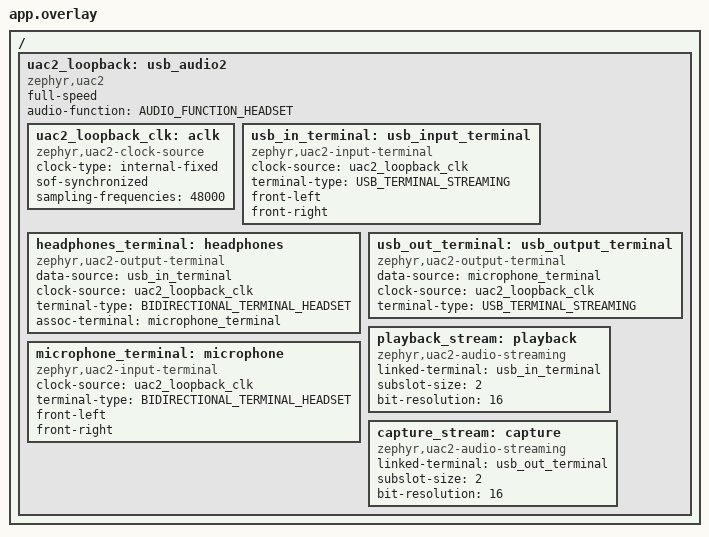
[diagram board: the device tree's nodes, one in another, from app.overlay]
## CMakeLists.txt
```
# SPDX-FileCopyrightText: Copyright The Zephyr Project Contributors
# SPDX-License-Identifier: Apache-2.0

cmake_minimum_required(VERSION 3.28.0)
find_package(Zephyr REQUIRED HINTS $ENV{ZEPHYR_BASE})
project(uac2_loopback)

include(${ZEPHYR_BASE}/samples/subsys/usb/common/common.cmake)
target_sources(app PRIVATE src/main.c)
```

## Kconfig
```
# SPDX-FileCopyrightText: Copyright The Zephyr Project Contributors
# SPDX-License-Identifier: Apache-2.0

source "samples/subsys/usb/common/Kconfig.sample_usbd"

source "Kconfig.zephyr"
```

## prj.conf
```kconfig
CONFIG_USB_DEVICE_STACK_NEXT=y
CONFIG_CDC_ACM_SERIAL_INITIALIZE_AT_BOOT=n
CONFIG_USBD_AUDIO2_CLASS=y
CONFIG_SAMPLE_USBD_PID=0x0014
CONFIG_SAMPLE_USBD_PRODUCT="UAC2 loopback sample"

CONFIG_LOG=y
CONFIG_USBD_LOG_LEVEL_WRN=y
CONFIG_UDC_DRIVER_LOG_LEVEL_WRN=y
```

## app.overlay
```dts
/*
 * SPDX-FileCopyrightText: Copyright The Zephyr Project Contributors
 * SPDX-License-Identifier: Apache-2.0
 */

#include <zephyr/dt-bindings/usb/audio.h>

/ {
	uac2_loopback: usb_audio2 {
		compatible = "zephyr,uac2";
		status = "okay";
		full-speed;
		audio-function = <AUDIO_FUNCTION_HEADSET>;

		uac2_loopback_clk: aclk {
			compatible = "zephyr,uac2-clock-source";
			clock-type = "internal-fixed";
			sof-synchronized;
			sampling-frequencies = <48000>;
		};

		usb_in_terminal: usb_input_terminal {
			compatible = "zephyr,uac2-input-terminal";
			clock-source = <&uac2_loopback_clk>;
			terminal-type = <USB_TERMINAL_STREAMING>;
			front-left;
			front-right;
		};

		headphones_terminal: headphones {
			compatible = "zephyr,uac2-output-terminal";
			data-source = <&usb_in_terminal>;
			clock-source = <&uac2_loopback_clk>;
			terminal-type = <BIDIRECTIONAL_TERMINAL_HEADSET>;
			assoc-terminal = <&microphone_terminal>;
		};

		microphone_terminal: microphone {
			compatible = "zephyr,uac2-input-terminal";
			clock-source = <&uac2_loopback_clk>;
			terminal-type = <BIDIRECTIONAL_TERMINAL_HEADSET>;
			front-left;
			front-right;
		};

		usb_out_terminal: usb_output_terminal {
			compatible = "zephyr,uac2-output-terminal";
			data-source = <&microphone_terminal>;
			clock-source = <&uac2_loopback_clk>;
			terminal-type = <USB_TERMINAL_STREAMING>;
		};

		playback_stream: playback {
			compatible = "zephyr,uac2-audio-streaming";
			linked-terminal = <&usb_in_terminal>;
			subslot-size = <2>;
			bit-resolution = <16>;
		};

		capture_stream: capture {
			compatible = "zephyr,uac2-audio-streaming";
			linked-terminal = <&usb_out_terminal>;
			subslot-size = <2>;
			bit-resolution = <16>;
		};
	};
};
```

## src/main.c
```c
/*
 * SPDX-FileCopyrightText: Copyright The Zephyr Project Contributors
 * SPDX-License-Identifier: Apache-2.0
 */

#include <string.h>

#include <sample_usbd.h>

#include <zephyr/kernel.h>
#include <zephyr/logging/log.h>
#include <zephyr/usb/class/usbd_uac2.h>
#include <zephyr/usb/usbd.h>

LOG_MODULE_REGISTER(uac2_loopback, LOG_LEVEL_INF);

#define PLAYBACK_TERMINAL_ID UAC2_ENTITY_ID(DT_NODELABEL(usb_in_terminal))
#define CAPTURE_TERMINAL_ID  UAC2_ENTITY_ID(DT_NODELABEL(usb_out_terminal))

#define SAMPLE_RATE          48000
#define SAMPLE_WIDTH_BYTES   2
#define CHANNEL_COUNT        2
#define FRAME_SIZE           (SAMPLE_RATE / 1000 * SAMPLE_WIDTH_BYTES * CHANNEL_COUNT)
#define BUFFER_COUNT         4

K_MEM_SLAB_DEFINE_STATIC(audio_slab, ROUND_UP(FRAME_SIZE, UDC_BUF_GRANULARITY),
			 BUFFER_COUNT, UDC_BUF_ALIGN);

struct loopback_context {
	void *pending;
	uint16_t pending_size;
	bool capture_enabled;
};

static void *get_recv_buf(const struct device *dev, uint8_t terminal,
			  uint16_t size, void *user_data)
{
	void *buf;

	ARG_UNUSED(dev);
	ARG_UNUSED(user_data);

	if (terminal != PLAYBACK_TERMINAL_ID || size > FRAME_SIZE ||
	    k_mem_slab_alloc(&audio_slab, &buf, K_NO_WAIT) != 0) {
		return NULL;
	}

	return buf;
}

static void data_received(const struct device *dev, uint8_t terminal,
			  void *buf, uint16_t size, void *user_data)
{
	struct loopback_context *ctx = user_data;

	ARG_UNUSED(dev);

	if (terminal != PLAYBACK_TERMINAL_ID || size == 0) {
		k_mem_slab_free(&audio_slab, buf);
		return;
	}

	if (ctx->pending != NULL) {
		k_mem_slab_free(&audio_slab, ctx->pending);
	}

	ctx->pending = buf;
	ctx->pending_size = size;
}

static void buffer_released(const struct device *dev, uint8_t terminal,
			    void *buf, void *user_data)
{
	ARG_UNUSED(dev);
	ARG_UNUSED(user_data);

	if (terminal == CAPTURE_TERMINAL_ID) {
		k_mem_slab_free(&audio_slab, buf);
	}
}

static void terminal_updated(const struct device *dev, uint8_t terminal,
			     bool enabled, bool microframes, void *user_data)
{
	struct loopback_context *ctx = user_data;

	ARG_UNUSED(dev);
	ARG_UNUSED(microframes);

	if (terminal == CAPTURE_TERMINAL_ID) {
		ctx->capture_enabled = enabled;
	}
}

static void start_of_frame(const struct device *dev, void *user_data)
{
	struct loopback_context *ctx = user_data;
	void *buf = ctx->pending;
	uint16_t size = ctx->pending_size;

	ctx->pending = NULL;
	ctx->pending_size = 0;

	if (!ctx->capture_enabled) {
		if (buf != NULL) {
			k_mem_slab_free(&audio_slab, buf);
		}
		return;
	}

	if (buf == NULL) {
		if (k_mem_slab_alloc(&audio_slab, &buf, K_NO_WAIT) != 0) {
			return;
		}

		size = FRAME_SIZE;
		memset(buf, 0, size);
	}

	if (usbd_uac2_send(dev, CAPTURE_TERMINAL_ID, buf, size) != 0) {
		k_mem_slab_free(&audio_slab, buf);
	}
}

static const struct uac2_ops audio_ops = {
	.sof_cb = start_of_frame,
	.terminal_update_cb = terminal_updated,
	.get_recv_buf = get_recv_buf,
	.data_recv_cb = data_received,
	.buf_release_cb = buffer_released,
};

static struct loopback_context loopback;

int main(void)
{
	const struct device *uac2 = DEVICE_DT_GET(DT_NODELABEL(uac2_loopback));
	struct usbd_context *sample_usbd;
	int ret;

	if (!device_is_ready(uac2)) {
		LOG_ERR("UAC2 device is not ready");
		return -ENODEV;
	}

	usbd_uac2_set_ops(uac2, &audio_ops, &loopback);

	sample_usbd = sample_usbd_init_device(NULL);
	if (sample_usbd == NULL) {
		return -ENODEV;
	}

	ret = usbd_enable(sample_usbd);
	if (ret != 0) {
		LOG_ERR("Failed to enable USB device support: %d", ret);
		return ret;
	}

	LOG_INF("USB audio loopback enabled");
	return 0;
}
```
